# EFM32TG11B120F128GM64 register map
File version: 4.0.0
CPU: CM0PLUS r0p1, little endian, MPU, no FPU, 3 interrupt priority bits
Registers are 32-bit, read-write, reset 0x0 unless marked. A register's access mark holds for its fields unless they carry their own. Offsets are from the block's base; [hi:lo] are bit positions; {n}, {i} and the like mark numbered series.

## PRS
Base 0x400E6000
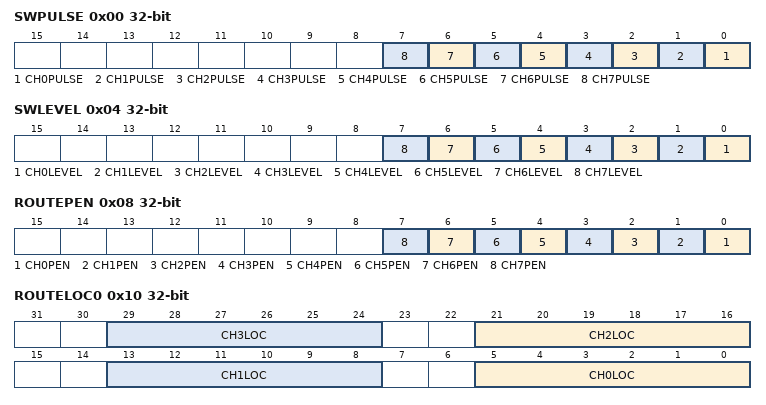
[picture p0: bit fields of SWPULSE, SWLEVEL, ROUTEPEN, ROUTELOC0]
0x00 SWPULSE wo — Software Pulse Register
  [n] CH{n}PULSE (n=0..7) — Channel {n} Pulse Generation
0x04 SWLEVEL — Software Level Register
  [n] CH{n}LEVEL (n=0..7) — Channel {n} Software Level
0x08 ROUTEPEN — I/O Routing Pin Enable Register
  [n] CH{n}PEN (n=0..7) — CH{n} Pin Enable
0x10 ROUTELOC0 — I/O Routing Location Register
  [all] fields
    {v}=LOC{v} (Location {v}) (v=0..3)
  [8n+5:8n] CH{n}LOC (n=0..3) — I/O Location
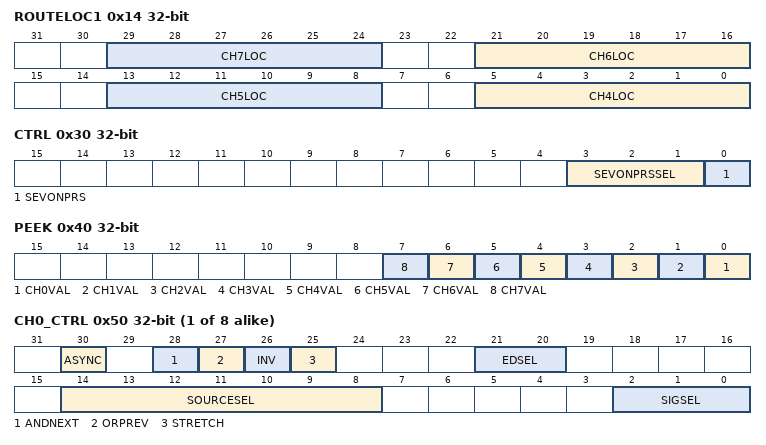
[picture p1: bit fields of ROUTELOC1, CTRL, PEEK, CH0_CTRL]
0x14 ROUTELOC1 — I/O Routing Location Register
  [all] fields
    0=LOC0 (Location 0); 1=LOC1 (Location 1); 2=LOC2 (Location 2)
  [8n-27:8n-32] CH{n}LOC (n=4..7) — I/O Location
0x30 CTRL — Control Register
  [3:1] SEVONPRSSEL — SEVONPRS PRS Channel Select
    {v}=PRSCH{v} (PRS Channel {v} selected) (v=0..7)
  [0] SEVONPRS — Set Event on PRS
0x34 DMAREQ0 — DMA Request 0 Register
  [8:6] PRSSEL — DMA Request 0 PRS Channel Select
    {v}=PRSCH{v} (PRS Channel {v} selected) (v=0..7)
0x38 DMAREQ1 — DMA Request 1 Register
  [8:6] PRSSEL — DMA Request 1 PRS Channel Select
    {v}=PRSCH{v} (PRS Channel {v} selected) (v=0..7)
0x40 PEEK ro — PRS Channel Values
  [n] CH{n}VAL (n=0..7) — Channel {n} Current Value
{0x50+4i} CH{i}_CTRL (i=0..7) — Channel Control Register
  [30] ASYNC — Asynchronous Reflex
  [28] ANDNEXT
  [27] ORPREV — Or Previous
  [26] INV — Invert Channel
  [25] STRETCH — Stretch Channel Output
  [21:20] EDSEL — Edge Detect Select
    0=OFF (Signal is left as it is); 1=POSEDGE (A one HFCLK cycle pulse is generated for every positive edge of the incoming signal); 2=NEGEDGE (A one HFCLK clock cycle pulse is generated for every negative edge of the incoming signal); 3=BOTHEDGES (A one HFCLK clock cycle pulse is generated for every edge of the incoming signal)
  [14:8] SOURCESEL — Source Select
    0=NONE (No source selected); 1=PRSL (Peripheral Reflex System); 2=ACMP0 (Analog Comparator 0); 3=ACMP1 (Analog Comparator 1); 4=ADC0 (Analog to Digital Converter 0); 5=RTCC (Real-Time Counter and Calendar); 6=GPIOL (General purpose Input/Output); 7=GPIOH (General purpose Input/Output); 8=LETIMER0 (Low Energy Timer 0); 9=PCNT0 (Pulse Counter 0); 10=CRYOTIMER; 11=CMU (Clock Management Unit); 17=VDAC0 (Digital to Analog Converter 0); 18=LESENSEL (Low Energy Sensor Interface); 19=LESENSEH (Low Energy Sensor Interface); 20=LESENSED (Low Energy Sensor Interface); 21=LESENSE (Low Energy Sensor Interface); {v}=USART{v-32} (Universal Synchronous/Asynchronous Receiver/Transmitter {v-32}) (v=32..35); 36=UART0 (Universal Asynchronous Receiver/Transmitter 0); 37=TIMER0; 38=TIMER1; 39=WTIMER0 (Wide Timer 0); 40=WTIMER1 (Wide Timer 1); 41=CM0P
  [2:0] SIGSEL — Signal Select
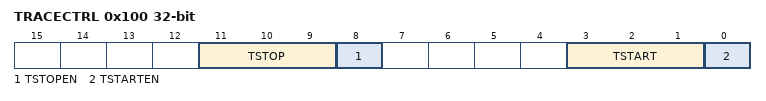
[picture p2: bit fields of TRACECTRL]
0x100 TRACECTRL — MTB Trace Control Register
  [11:9] TSTOP — MTB TSTOP PRS Select
    {v}=PRSCH{v} (PRS ch {v} is controlling TSTOP.) (v=0..7)
  [8] TSTOPEN — PRS TSTOP Enable
  [3:1] TSTART — MTB TSTART PRS Select
    {v}=PRSCH{v} (PRS ch {v} is controlling TSTART.) (v=0..7)
  [0] TSTARTEN — PRS TSTART Enable

## GPCRC
Base 0x4001C000
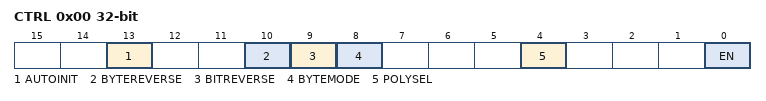
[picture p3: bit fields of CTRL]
0x00 CTRL — Control Register
  [13] AUTOINIT — Auto Init Enable
  [10] BYTEREVERSE — Byte Reverse Mode
  [9] BITREVERSE — Byte-level Bit Reverse Enable
  [8] BYTEMODE — Byte Mode Enable
  [4] POLYSEL — Polynomial Select
  [0] EN — CRC Functionality Enable
0x04 CMD wo — Command Register
  [0] INIT — Initialization Enable
0x08 INIT — CRC Init Value
  [31:0] INIT — CRC Initialization Value
0x0C POLY — CRC Polynomial Value
  [15:0] POLY
0x10 INPUTDATA — Input 32-bit Data Register
  [31:0] INPUTDATA — Input Data for 32-bit
0x14 INPUTDATAHWORD — Input 16-bit Data Register
  [15:0] INPUTDATAHWORD — Input Data for 16-bit
0x18 INPUTDATABYTE — Input 8-bit Data Register
  [7:0] INPUTDATABYTE — Input Data for 8-bit
0x1C DATA ro — CRC Data Register
0x20 DATAREV ro — CRC Data Reverse Register
  [31:0] DATAREV — Data Reverse Value
0x24 DATABYTEREV ro — CRC Data Byte Reverse Register
  [31:0] DATABYTEREV — Data Byte Reverse Value

## Notices in the file
# License
Copyright 2021 Silicon Laboratories Inc. www.silabs.com
SPDX-License-Identifier: Zlib
The licensor of this software is Silicon Laboratories Inc.
This software is provided 'as-is', without any express or implied
warranty. In no event will the authors be held liable for any damages
arising from the use of this software.
Permission is granted to anyone to use this software for any purpose,
including commercial applications, and to alter it and redistribute it
freely, subject to the following restrictions:
1. The origin of this software must not be misrepresented; you must not
claim that you wrote the original software. If you use this software
in a product, an acknowledgment in the product documentation would be
appreciated but is not required.
2. Altered source versions must be plainly marked as such, and must not be
misrepresented as being the original software.
3. This notice may not be removed or altered from any source distribution.
